# L4PER_PRM register map
Vendor: Texas Instruments
Registers are 32-bit, access per field, reset 0x0 unless marked. A register's access mark holds for its fields unless they carry their own. Offsets are as the file gives them; [hi:lo] are bit positions; {n}, {i} and the like mark numbered series; 'fields as' and 'values as' point back to an identical list.

## L4PER_PRM (part 2 of 2)
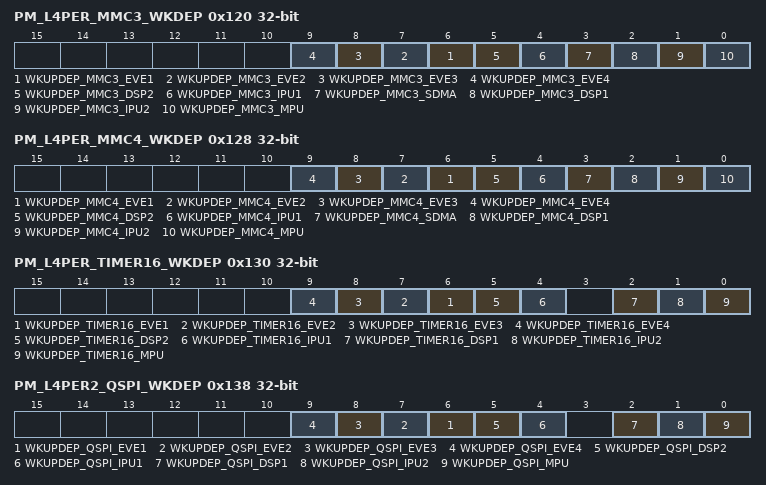
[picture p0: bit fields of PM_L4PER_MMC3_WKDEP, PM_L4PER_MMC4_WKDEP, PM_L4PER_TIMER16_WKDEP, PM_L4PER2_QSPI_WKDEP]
0x120 PM_L4PER_MMC3_WKDEP — This register controls wakeup dependency based on MMC3 service requests.
  [all] fields
    0=DISABLED (Dependency is disabled); 1=ENABLED (Dependency is enabled)
  [n+5] WKUPDEP_MMC3_EVE{n} rw (n=1..4) — Wakeup dependency from MMC3 module (SWakeup signal) towards EVE{n} + L3_MAIN1 + L4PER1 + L4PER2 + L4PER3 domains
  [5] WKUPDEP_MMC3_DSP2 rw — Wakeup dependency from MMC3 module (SWakeup signal) towards DSP2 + L3_MAIN1 + L4PER1 + L4PER2 + L4PER3 domains
  [4] WKUPDEP_MMC3_IPU1 rw — Wakeup dependency from MMC3 module (SWakeup signal) towards IPU1 + L3_MAIN1 + L4PER1 + L4PER2 + L4PER3 domains
  [3] WKUPDEP_MMC3_SDMA rw — Wakeup dependency from MMC3 module (SWakeup signal) towards SDMA + L3MAIN1 + L4PER1 + L4PER2 + L4PER3 domains
  [2] WKUPDEP_MMC3_DSP1 rw — Wakeup dependency from MMC3 module (SWakeup signal) towards DSP + L3MAIN1 + L4PER1 + L4PER2 + L4PER3 domains
  [1] WKUPDEP_MMC3_IPU2 rw — Wakeup dependency from MMC3 module (SWakeup signal) towards IPU2 + L3_MAIN1 + L4PER1 + L4PER2 + L4PER3 domains
  [0] WKUPDEP_MMC3_MPU rw — Wakeup dependency from MMC3 module (SWakeup signal) towards MPU + L3_MAIN1 + L4PER1 + L4PER2 + L4PER3 domains
0x128 PM_L4PER_MMC4_WKDEP — This register controls wakeup dependency based on MMC4 service requests.
  [all] fields
    values as the fields of PM_L4PER_MMC3_WKDEP
  [n+5] WKUPDEP_MMC4_EVE{n} rw (n=1..4) — Wakeup dependency from MMC4 module (SWakeup signal) towards EVE{n} + L3_MAIN1 + L4PER1 + L4PER2 + L4PER3 domains
  [5] WKUPDEP_MMC4_DSP2 rw — Wakeup dependency from MMC4 module (SWakeup signal) towards DSP2 + L3_MAIN1 + L4PER1 + L4PER2 + L4PER3 domains
  [4] WKUPDEP_MMC4_IPU1 rw — Wakeup dependency from MMC4 module (SWakeup signal) towards IPU1 + L3_MAIN1 + L4PER1 + L4PER2 + L4PER3 domains
  [3] WKUPDEP_MMC4_SDMA rw — Wakeup dependency from MMC4 module (SWakeup signal) towards SDMA + L3MAIN1 + L4PER1 + L4PER2 + L4PER3 domains
  [2] WKUPDEP_MMC4_DSP1 rw — Wakeup dependency from MMC4 module (SWakeup signal) towards DSP + L3MAIN1 + L4PER1 + L4PER2 + L4PER3 domains
  [1] WKUPDEP_MMC4_IPU2 rw — Wakeup dependency from MMC4 module (SWakeup signal) towards IPU2 + L3_MAIN1 + L4PER1 + L4PER2 + L4PER3 domains
  [0] WKUPDEP_MMC4_MPU rw — Wakeup dependency from MMC4 module (SWakeup signal) towards MPU + L3_MAIN1 + L4PER1 + L4PER2 + L4PER3 domains
0x130 PM_L4PER_TIMER16_WKDEP — This register controls wakeup dependency based on TIMER16 service requests.
  [all] fields
    values as the fields of PM_L4PER_MMC3_WKDEP
  [n+5] WKUPDEP_TIMER16_EVE{n} rw (n=1..4) — Wakeup dependency from TIMER16 module (SWakeup IRQ signal) towards EVE{n} + L3_MAIN1 + L4PER1 + L4PER2 + L4PER3 domains
  [5] WKUPDEP_TIMER16_DSP2 rw — Wakeup dependency from TIMER16 module (SWakeup IRQ signal) towards DSP2 + L3_MAIN1 + L4PER1 + L4PER2 + L4PER3 domains
  [4] WKUPDEP_TIMER16_IPU1 rw — Wakeup dependency from TIMER16 module (SWakeup IRQ signal) towards IPU1 + L3_MAIN1 + L4PER1 + L4PER2 + L4PER3 domains
  [2] WKUPDEP_TIMER16_DSP1 rw — Wakeup dependency from TIMER16 module (SWakeup IRQ signal) towards DSP + L3MAIN1 + L4PER1 + L4PER2 + L4PER3 domains
  [1] WKUPDEP_TIMER16_IPU2 rw — Wakeup dependency from TIMER16 module (SWakeup IRQ signal) towards IPU2 + L3_MAIN1 + L4PER1 + L4PER2 + L4PER3 domains
  [0] WKUPDEP_TIMER16_MPU rw — 6Wakeup dependency from TIMER16 module (SWakeup IRQ signal) towards MPU + L3_MAIN1 + L4PER1 + L4PER2 + L4PER3 domains
0x138 PM_L4PER2_QSPI_WKDEP — This register controls wakeup dependency based on QSPI service requests.
  [all] fields
    values as the fields of PM_L4PER_MMC3_WKDEP
  [n+5] WKUPDEP_QSPI_EVE{n} rw (n=1..4) — Wakeup dependency from QSPI module (SWakeup IRQ signal) towards EVE{n} + L3_MAIN1 + L4PER1 + L4PER2 + L4PER3 domains
  [5] WKUPDEP_QSPI_DSP2 rw — Wakeup dependency from QSPI module (SWakeup IRQ signal) towards DSP2 + L3_MAIN1 + L4PER1 + L4PER2 + L4PER3 domains
  [4] WKUPDEP_QSPI_IPU1 rw — Wakeup dependency from QSPI module (SWakeup IRQ signal) towards IPU1 + L3_MAIN1 + L4PER1 + L4PER2 + L4PER3 domains
  [2] WKUPDEP_QSPI_DSP1 rw — Wakeup dependency from QSPI module (SWakeup IRQ signal) towards DSP + L3MAIN1 + L4PER1 + L4PER2 + L4PER3 domains
  [1] WKUPDEP_QSPI_IPU2 rw — Wakeup dependency from QSPI module (SWakeup IRQ signal) towards IPU2 + L3_MAIN1 + L4PER1 + L4PER2 + L4PER3 domains
  [0] WKUPDEP_QSPI_MPU rw — Wakeup dependency from QSPI module (SWakeup IRQ signal) towards MPU + L3_MAIN1 + L4PER1 + L4PER2 + L4PER3 domains
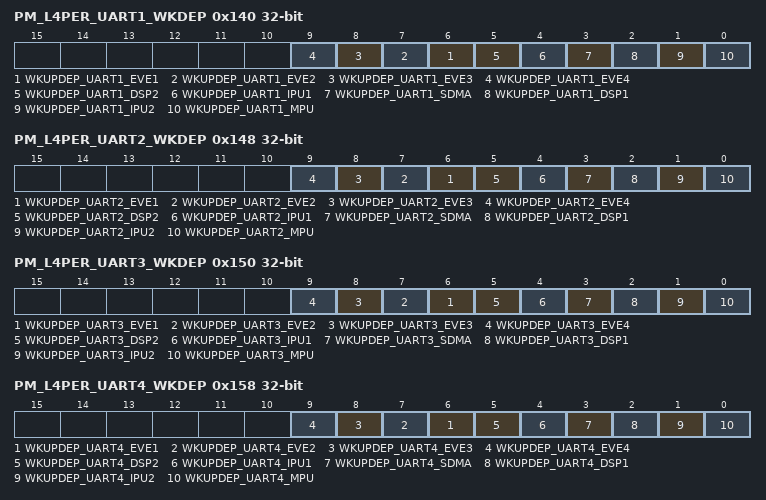
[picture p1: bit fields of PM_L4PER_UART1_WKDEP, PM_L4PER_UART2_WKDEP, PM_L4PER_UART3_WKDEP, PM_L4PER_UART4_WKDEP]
0x140 PM_L4PER_UART1_WKDEP — This register controls wakeup dependency based on UART1 service requests.
  [all] fields
    values as the fields of PM_L4PER_MMC3_WKDEP
  [n+5] WKUPDEP_UART1_EVE{n} rw (n=1..4) — Wakeup dependency from UART1 module (SWakeup signal) towards EVE{n} + L3_MAIN1 + L4PER1 + L4PER2 + L4PER3 domains
  [5] WKUPDEP_UART1_DSP2 rw — Wakeup dependency from UART1 module (SWakeup signal) towards DSP2 + L3_MAIN1 + L4PER1 + L4PER2 + L4PER3 domains
  [4] WKUPDEP_UART1_IPU1 rw — Wakeup dependency from UART1 module (SWakeup signal) towards IPU1 + L3_MAIN1 + L4PER1 + L4PER2 + L4PER3 domains
  [3] WKUPDEP_UART1_SDMA rw — Wakeup dependency from UART1 module (SWakeup signal) towards SDMA + L3MAIN1 + L4PER1 + L4PER2 + L4PER3 domains
  [2] WKUPDEP_UART1_DSP1 rw — Wakeup dependency from UART1 module (SWakeup signal) towards DSP + L3MAIN1 + L4PER1 + L4PER2 + L4PER3 domains
  [1] WKUPDEP_UART1_IPU2 rw — Wakeup dependency from UART1 module (SWakeup signal) towards IPU2 + L3_MAIN1 + L4PER1 + L4PER2 + L4PER3 domains
  [0] WKUPDEP_UART1_MPU rw — Wakeup dependency from UART1 module (SWakeup signal) towards MPU + L3_MAIN1 + L4PER1 + L4PER2 + L4PER3 domains
0x148 PM_L4PER_UART2_WKDEP — This register controls wakeup dependency based on UART2 service requests.
  [all] fields
    values as the fields of PM_L4PER_MMC3_WKDEP
  [n+5] WKUPDEP_UART2_EVE{n} rw (n=1..4) — Wakeup dependency from UART2 module (SWakeup signal) towards EVE{n} + L3_MAIN1 + L4PER1 + L4PER2 + L4PER3 domains
  [5] WKUPDEP_UART2_DSP2 rw — Wakeup dependency from UART2 module (SWakeup signal) towards DSP2 + L3_MAIN1 + L4PER1 + L4PER2 + L4PER3 domains
  [4] WKUPDEP_UART2_IPU1 rw — Wakeup dependency from UART2 module (SWakeup signal) towards IPU1 + L3_MAIN1 + L4PER1 + L4PER2 + L4PER3 domains
  [3] WKUPDEP_UART2_SDMA rw — 2Wakeup dependency from UART2 module (SWakeup signal) towards SDMA + L3MAIN1 + L4PER1 + L4PER2 + L4PER3 domains
  [2] WKUPDEP_UART2_DSP1 rw — Wakeup dependency from UART2 module (SWakeup signal) towards DSP + L3MAIN1 + L4PER1 + L4PER2 + L4PER3 domains
  [1] WKUPDEP_UART2_IPU2 rw — Wakeup dependency from UART2 module (SWakeup signal) towards IPU2 + L3_MAIN1 + L4PER1 + L4PER2 + L4PER3 domains
  [0] WKUPDEP_UART2_MPU rw — Wakeup dependency from UART2 module (SWakeup signal) towards MPU + L3_MAIN1 + L4PER1 + L4PER2 + L4PER3 domains
0x150 PM_L4PER_UART3_WKDEP — This register controls wakeup dependency based on UART3 service requests.
  [all] fields
    values as the fields of PM_L4PER_MMC3_WKDEP
  [n+5] WKUPDEP_UART3_EVE{n} rw (n=1..4) — Wakeup dependency from UART3 module (SWakeup signal) towards EVE{n} + L3_MAIN1 + L4PER1 + L4PER2 + L4PER3 domains
  [5] WKUPDEP_UART3_DSP2 rw — Wakeup dependency from UART3 module (SWakeup signal) towards DSP2 + L3_MAIN1 + L4PER1 + L4PER2 + L4PER3 domains
  [4] WKUPDEP_UART3_IPU1 rw — Wakeup dependency from UART3 module (SWakeup signal) towards IPU1 + L3_MAIN1 + L4PER1 + L4PER2 + L4PER3 domains
  [3] WKUPDEP_UART3_SDMA rw — Wakeup dependency from UART3 module (SWakeup signal) towards SDMA + L3MAIN1 + L4PER1 + L4PER2 + L4PER3 domains
  [2] WKUPDEP_UART3_DSP1 rw — Wakeup dependency from UART3 module (SWakeup signal) towards DSP + L3MAIN1 + L4PER1 + L4PER2 + L4PER3 domains
  [1] WKUPDEP_UART3_IPU2 rw — Wakeup dependency from UART3 module (SWakeup signal) towards IPU2 + L3_MAIN1 + L4PER1 + L4PER2 + L4PER3 domains
  [0] WKUPDEP_UART3_MPU rw — Wakeup dependency from UART3 module (SWakeup signal) towards MPU + L3_MAIN1 + L4PER1 + L4PER2 + L4PER3 domains
0x158 PM_L4PER_UART4_WKDEP — This register controls wakeup dependency based on UART4 service requests.
  [all] fields
    values as the fields of PM_L4PER_MMC3_WKDEP
  [n+5] WKUPDEP_UART4_EVE{n} rw (n=1..4) — Wakeup dependency from UART4 module (SWakeup signal) towards EVE{n} + L3_MAIN1 + L4PER1 + L4PER2 + L4PER3 domains
  [5] WKUPDEP_UART4_DSP2 rw — Wakeup dependency from UART4 module (SWakeup signal) towards DSP2 + L3_MAIN1 + L4PER1 + L4PER2 + L4PER3 domains
  [4] WKUPDEP_UART4_IPU1 rw — Wakeup dependency from UART4 module (SWakeup signal) towards IPU1 + L3_MAIN1 + L4PER1 + L4PER2 + L4PER3 domains
  [3] WKUPDEP_UART4_SDMA rw — Wakeup dependency from UART4 module (SWakeup signal) towards SDMA + L3MAIN1 + L4PER1 + L4PER2 + L4PER3 domains
  [2] WKUPDEP_UART4_DSP1 rw — Wakeup dependency from UART4 module (SWakeup signal) towards DSP + L3MAIN1 + L4PER1 + L4PER2 + L4PER3 domains
  [1] WKUPDEP_UART4_IPU2 rw — Wakeup dependency from UART4 module (SWakeup signal) towards IPU2 + L3_MAIN1 + L4PER1 + L4PER2 + L4PER3 domains
  [0] WKUPDEP_UART4_MPU rw — Wakeup dependency from UART4 module (SWakeup signal) towards MPU + L3_MAIN1 + L4PER1 + L4PER2 + L4PER3 domains
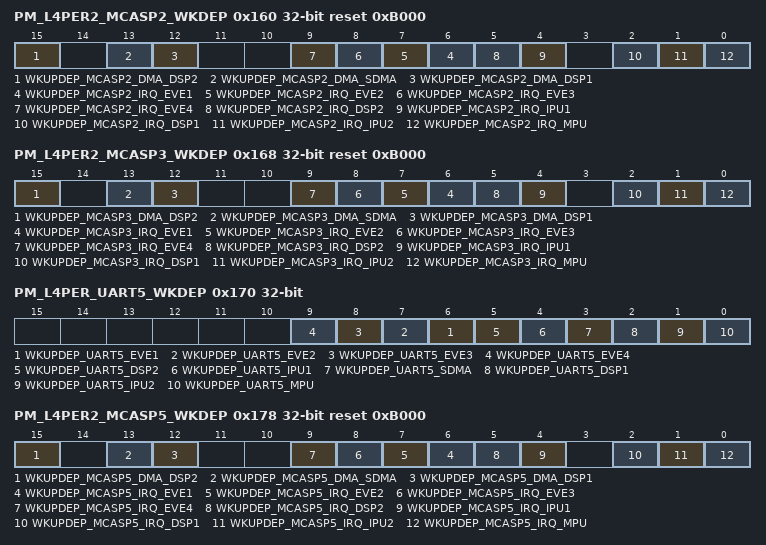
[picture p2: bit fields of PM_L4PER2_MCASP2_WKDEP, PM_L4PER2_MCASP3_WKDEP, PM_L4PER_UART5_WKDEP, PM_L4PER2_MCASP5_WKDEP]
0x160 PM_L4PER2_MCASP2_WKDEP reset 0xB000 — This register controls wakeup dependency based on MCASP2 service requests.
  [all] fields
    values as the fields of PM_L4PER_MMC3_WKDEP
  [15] WKUPDEP_MCASP2_DMA_DSP2 rw — Wakeup dependency from MCASP2 module (SWakeup_dma signal) towards DSP2 + L3_MAIN1 + L4PER1 + L4PER2 + L4PER3 domains
  [13] WKUPDEP_MCASP2_DMA_SDMA rw — Wakeup dependency from MCASP2 module (SWakeup_dma signal) towards SDMA + L3MAIN1 + L4PER1 + L4PER2 + L4PER3 domains
  [12] WKUPDEP_MCASP2_DMA_DSP1 rw — Wakeup dependency from MCASP2 module (SWakeup_dma signal) towards DSP + L3MAIN1 + L4PER1 + L4PER2 + L4PER3 domains
  [n+5] WKUPDEP_MCASP2_IRQ_EVE{n} rw (n=1..4) — Wakeup dependency from MCASP2 module (SWakeup IRQ signal) towards EVE{n} + L3_MAIN1 + L4PER1 + L4PER2 + L4PER3 domains
  [5] WKUPDEP_MCASP2_IRQ_DSP2 rw — Wakeup dependency from MCASP2 module (SWakeup IRQ signal) towards DSP2 + L3_MAIN1 + L4PER1 + L4PER2 + L4PER3 domains
  [4] WKUPDEP_MCASP2_IRQ_IPU1 rw — Wakeup dependency from MCASP2 module (SWakeup IRQ signal) towards IPU1 + L3_MAIN1 + L4PER1 + L4PER2 + L4PER3 domains
  [2] WKUPDEP_MCASP2_IRQ_DSP1 rw — Wakeup dependency from MCASP2 module (SWakeup IRQ signal) towards DSP + L3MAIN1 + L4PER1 + L4PER2 + L4PER3 domains
  [1] WKUPDEP_MCASP2_IRQ_IPU2 rw — Wakeup dependency from MCASP2 module (SWakeup IRQ signal) towards IPU2 + L3_MAIN1 + L4PER1 + L4PER2 + L4PER3 domains
  [0] WKUPDEP_MCASP2_IRQ_MPU rw — Wakeup dependency from MCASP2 module (SWakeup IRQ signal) towards MPU + L3_MAIN1 + L4PER1 + L4PER2 + L4PER3 domains
0x168 PM_L4PER2_MCASP3_WKDEP reset 0xB000 — This register controls wakeup dependency based on MCASP3 service requests.
  [all] fields
    values as the fields of PM_L4PER_MMC3_WKDEP
  [15] WKUPDEP_MCASP3_DMA_DSP2 rw — Wakeup dependency from MCASP3 module (SWakeup_dma signal) towards DSP2 + L3_MAIN1 + L4PER1 + L4PER2 + L4PER3 domains
  [13] WKUPDEP_MCASP3_DMA_SDMA rw — Wakeup dependency from MCASP3 module (SWakeup_dma signal) towards SDMA + L3MAIN1 + L4PER1 + L4PER2 + L4PER3 domains
  [12] WKUPDEP_MCASP3_DMA_DSP1 rw — 3Wakeup dependency from MCASP3 module (SWakeup_dma signal) towards DSP + L3MAIN1 + L4PER1 + L4PER2 + L4PER3 domains
  [n+5] WKUPDEP_MCASP3_IRQ_EVE{n} rw (n=1..4) — Wakeup dependency from MCASP3 module (SWakeup IRQ signal) towards EVE{n} + L3_MAIN1 + L4PER1 + L4PER2 + L4PER3 domains
  [5] WKUPDEP_MCASP3_IRQ_DSP2 rw — Wakeup dependency from MCASP3 module (SWakeup IRQ signal) towards DSP2 + L3_MAIN1 + L4PER1 + L4PER2 + L4PER3 domains
  [4] WKUPDEP_MCASP3_IRQ_IPU1 rw — Wakeup dependency from MCASP3 module (SWakeup IRQ signal) towards IPU1 + L3_MAIN1 + L4PER1 + L4PER2 + L4PER3 domains
  [2] WKUPDEP_MCASP3_IRQ_DSP1 rw — Wakeup dependency from MCASP3 module (SWakeup IRQ signal) towards DSP + L3MAIN1 + L4PER1 + L4PER2 + L4PER3 domains
  [1] WKUPDEP_MCASP3_IRQ_IPU2 rw — Wakeup dependency from MCASP3 module (SWakeup IRQ signal) towards IPU2 + L3_MAIN1 + L4PER1 + L4PER2 + L4PER3 domains
  [0] WKUPDEP_MCASP3_IRQ_MPU rw — Wakeup dependency from MCASP3 module (SWakeup IRQ signal) towards MPU + L3_MAIN1 + L4PER1 + L4PER2 + L4PER3 domains
0x170 PM_L4PER_UART5_WKDEP — This register controls wakeup dependency based on UART5 service requests.
  [all] fields
    values as the fields of PM_L4PER_MMC3_WKDEP
  [n+5] WKUPDEP_UART5_EVE{n} rw (n=1..4) — Wakeup dependency from UART5 module (SWakeup signal) towards EVE{n} + L3_MAIN1 + L4PER1 + L4PER2 + L4PER3 domains
  [5] WKUPDEP_UART5_DSP2 rw — Wakeup dependency from UART5 module (SWakeup signal) towards DSP2 + L3_MAIN1 + L4PER1 + L4PER2 + L4PER3 domains
  [4] WKUPDEP_UART5_IPU1 rw — Wakeup dependency from UART5 module (SWakeup signal) towards IPU1 + L3_MAIN1 + L4PER1 + L4PER2 + L4PER3 domains
  [3] WKUPDEP_UART5_SDMA rw — Wakeup dependency from UART5 module (SWakeup signal) towards SDMA + L3MAIN1 + L4PER1 + L4PER2 + L4PER3 domains
  [2] WKUPDEP_UART5_DSP1 rw — Wakeup dependency from UART5 module (SWakeup signal) towards DSP + L3MAIN1 + L4PER1 + L4PER2 + L4PER3 domains
  [1] WKUPDEP_UART5_IPU2 rw — Wakeup dependency from UART5 module (SWakeup signal) towards IPU2 + L3_MAIN1 + L4PER1 + L4PER2 + L4PER3 domains
  [0] WKUPDEP_UART5_MPU rw — Wakeup dependency from UART5 module (SWakeup signal) towards MPU + L3_MAIN1 + L4PER1 + L4PER2 + L4PER3 domains
0x178 PM_L4PER2_MCASP5_WKDEP reset 0xB000 — This register controls wakeup dependency based on MCASP5 service requests.
  [all] fields
    values as the fields of PM_L4PER_MMC3_WKDEP
  [15] WKUPDEP_MCASP5_DMA_DSP2 rw — Wakeup dependency from MCASP5 module (SWakeup_dma signal) towards DSP2 + L3_MAIN1 + L4PER1 + L4PER2 + L4PER3 domains
  [13] WKUPDEP_MCASP5_DMA_SDMA rw — Wakeup dependency from MCASP5 module (SWakeup_dma signal) towards SDMA + L3MAIN1 + L4PER1 + L4PER2 + L4PER3 domains
  [12] WKUPDEP_MCASP5_DMA_DSP1 rw — Wakeup dependency from MCASP5 module (SWakeup_dma signal) towards DSP + L3MAIN1 + L4PER1 + L4PER2 + L4PER3 domains
  [n+5] WKUPDEP_MCASP5_IRQ_EVE{n} rw (n=1..4) — Wakeup dependency from MCASP5 module (SWakeup IRQ signal) towards EVE{n} + L3_MAIN1 + L4PER1 + L4PER2 + L4PER3 domains
  [5] WKUPDEP_MCASP5_IRQ_DSP2 rw — Wakeup dependency from MCASP5 module (SWakeup IRQ signal) towards DSP2 + L3_MAIN1 + L4PER1 + L4PER2 + L4PER3 domains
  [4] WKUPDEP_MCASP5_IRQ_IPU1 rw — Wakeup dependency from MCASP5 module (SWakeup IRQ signal) towards IPU1 + L3_MAIN1 + L4PER1 + L4PER2 + L4PER3 domains
  [2] WKUPDEP_MCASP5_IRQ_DSP1 rw — Wakeup dependency from MCASP5 module (SWakeup IRQ signal) towards DSP + L3MAIN1 + L4PER1 + L4PER2 + L4PER3 domains
  [1] WKUPDEP_MCASP5_IRQ_IPU2 rw — Wakeup dependency from MCASP5 module (SWakeup IRQ signal) towards IPU2 + L3_MAIN1 + L4PER1 + L4PER2 + L4PER3 domains
  [0] WKUPDEP_MCASP5_IRQ_MPU rw — Wakeup dependency from MCASP5 module (SWakeup IRQ signal) towards MPU + L3_MAIN1 + L4PER1 + L4PER2 + L4PER3 domains
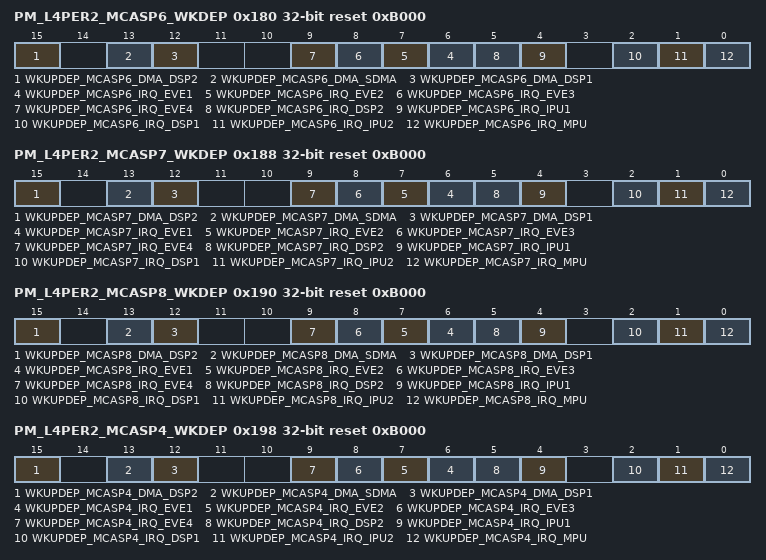
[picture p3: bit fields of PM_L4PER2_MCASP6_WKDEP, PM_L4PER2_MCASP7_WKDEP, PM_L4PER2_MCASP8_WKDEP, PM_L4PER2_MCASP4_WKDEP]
0x180 PM_L4PER2_MCASP6_WKDEP reset 0xB000 — This register controls wakeup dependency based on MCASP6 service requests.
  [all] fields
    values as the fields of PM_L4PER_MMC3_WKDEP
  [15] WKUPDEP_MCASP6_DMA_DSP2 rw — Wakeup dependency from MCASP6 module (SWakeup_dma signal) towards DSP2 + L3_MAIN1 + L4PER1 + L4PER2 + L4PER3 domains
  [13] WKUPDEP_MCASP6_DMA_SDMA rw — Wakeup dependency from MCASP6 module (SWakeup_dma signal) towards SDMA + L3MAIN1 + L4PER1 + L4PER2 + L4PER3 domains
  [12] WKUPDEP_MCASP6_DMA_DSP1 rw — Wakeup dependency from MCASP6 module (SWakeup_dma signal) towards DSP + L3MAIN1 + L4PER1 + L4PER2 + L4PER3 domains
  [n+5] WKUPDEP_MCASP6_IRQ_EVE{n} rw (n=1..4) — Wakeup dependency from MCASP6 module (SWakeup IRQ signal) towards EVE{n} + L3_MAIN1 + L4PER1 + L4PER2 + L4PER3 domains
  [5] WKUPDEP_MCASP6_IRQ_DSP2 rw — Wakeup dependency from MCASP6 module (SWakeup IRQ signal) towards DSP2 + L3_MAIN1 + L4PER1 + L4PER2 + L4PER3 domains
  [4] WKUPDEP_MCASP6_IRQ_IPU1 rw — Wakeup dependency from MCASP6 module (SWakeup IRQ signal) towards IPU1 + L3_MAIN1 + L4PER1 + L4PER2 + L4PER3 domains
  [2] WKUPDEP_MCASP6_IRQ_DSP1 rw — Wakeup dependency from MCASP6 module (SWakeup IRQ signal) towards DSP + L3MAIN1 + L4PER1 + L4PER2 + L4PER3 domains
  [1] WKUPDEP_MCASP6_IRQ_IPU2 rw — Wakeup dependency from MCASP6 (SWakeup IRQ signal) towards IPU2 + L3_MAIN1 + L4PER1 + L4PER2 + L4PER3 domains
  [0] WKUPDEP_MCASP6_IRQ_MPU rw — Wakeup dependency from MCASP6 module (SWakeup IRQ signal) towards MPU + L3_MAIN1 + L4PER1 + L4PER2 + L4PER3 domains
0x188 PM_L4PER2_MCASP7_WKDEP reset 0xB000 — This register controls wakeup dependency based on MCASP7 service requests.
  [all] fields
    values as the fields of PM_L4PER_MMC3_WKDEP
  [15] WKUPDEP_MCASP7_DMA_DSP2 rw — Wakeup dependency from MCASP7 module (SWakeup_dma signal) towards DSP2 + L3_MAIN1 + L4PER1 + L4PER2 + L4PER3 domains
  [13] WKUPDEP_MCASP7_DMA_SDMA rw — Wakeup dependency from MCASP7 module (SWakeup_dma signal) towards SDMA + L3MAIN1 + L4PER1 + L4PER2 + L4PER3 domains
  [12] WKUPDEP_MCASP7_DMA_DSP1 rw — Wakeup dependency from MCASP7 module (SWakeup_dma signal) towards DSP + L3MAIN1 + L4PER1 + L4PER2 + L4PER3 domains
  [n+5] WKUPDEP_MCASP7_IRQ_EVE{n} rw (n=1..4) — Wakeup dependency from MCASP7 module (SWakeup IRQ signal) towards EVE{n} + L3_MAIN1 + L4PER1 + L4PER2 + L4PER3 domains
  [5] WKUPDEP_MCASP7_IRQ_DSP2 rw — Wakeup dependency from MCASP7 module (SWakeup IRQ signal) towards DSP2 + L3_MAIN1 + L4PER1 + L4PER2 + L4PER3 domains
  [4] WKUPDEP_MCASP7_IRQ_IPU1 rw — Wakeup dependency from MCASP7 module (SWakeup IRQ signal) towards IPU1 + L3_MAIN1 + L4PER1 + L4PER2 + L4PER3 domains
  [2] WKUPDEP_MCASP7_IRQ_DSP1 rw — Wakeup dependency from MCASP7 module (SWakeup IRQ signal) towards DSP + L3MAIN1 + L4PER1 + L4PER2 + L4PER3 domains
  [1] WKUPDEP_MCASP7_IRQ_IPU2 rw — Wakeup dependency from MCASP7 module (SWakeup IRQ signal) towards IPU2 + L3_MAIN1 + L4PER1 + L4PER2 + L4PER3 domains
  [0] WKUPDEP_MCASP7_IRQ_MPU rw — Wakeup dependency from MCASP7 module (SWakeup IRQ signal) towards MPU + L3_MAIN1 + L4PER1 + L4PER2 + L4PER3 domains
0x190 PM_L4PER2_MCASP8_WKDEP reset 0xB000 — This register controls wakeup dependency based on MCASP8 service requests.
  [all] fields
    values as the fields of PM_L4PER_MMC3_WKDEP
  [15] WKUPDEP_MCASP8_DMA_DSP2 rw — Wakeup dependency from MCASP8 module (SWakeup_dma signal) towards DSP2 + L3_MAIN1 + L4PER1 + L4PER2 + L4PER3 domains
  [13] WKUPDEP_MCASP8_DMA_SDMA rw — Wakeup dependency from MCASP8 module (SWakeup_dma signal) towards SDMA + L3MAIN1 + L4PER1 + L4PER2 + L4PER3 domains
  [12] WKUPDEP_MCASP8_DMA_DSP1 rw — Wakeup dependency from MCASP8 module (SWakeup_dma signal) towards DSP + L3MAIN1 + L4PER1 + L4PER2 + L4PER3 domains
  [n+5] WKUPDEP_MCASP8_IRQ_EVE{n} rw (n=1..4) — Wakeup dependency from MCASP8 module (SWakeup IRQ signal) towards EVE{n} + L3_MAIN1 + L4PER1 + L4PER2 + L4PER3 domains
  [5] WKUPDEP_MCASP8_IRQ_DSP2 rw — Wakeup dependency from MCASP8 module (SWakeup IRQ signal) towards DSP2 + L3_MAIN1 + L4PER1 + L4PER2 + L4PER3 domains
  [4] WKUPDEP_MCASP8_IRQ_IPU1 rw — Wakeup dependency from MCASP8 module (SWakeup IRQ signal) towards IPU1 + L3_MAIN1 + L4PER1 + L4PER2 + L4PER3 domains
  [2] WKUPDEP_MCASP8_IRQ_DSP1 rw — Wakeup dependency from MCASP8 module (SWakeup IRQ signal) towards DSP + L3MAIN1 + L4PER1 + L4PER2 + L4PER3 domains
  [1] WKUPDEP_MCASP8_IRQ_IPU2 rw — Wakeup dependency from MCASP8 module (SWakeup IRQ signal) towards IPU2 + L3_MAIN1 + L4PER1 + L4PER2 + L4PER3 domains
  [0] WKUPDEP_MCASP8_IRQ_MPU rw — Wakeup dependency from MCASP8 module (SWakeup IRQ signal) towards MPU + L3_MAIN1 + L4PER1 + L4PER2 + L4PER3 domains
0x198 PM_L4PER2_MCASP4_WKDEP reset 0xB000 — This register controls wakeup dependency based on MCASP4 service requests.
  [all] fields
    values as the fields of PM_L4PER_MMC3_WKDEP
  [15] WKUPDEP_MCASP4_DMA_DSP2 rw — Wakeup dependency from MCASP4 module (SWakeup_dma signal) towards DSP2 + L3_MAIN1 + L4PER1 + L4PER2 + L4PER3 domains
  [13] WKUPDEP_MCASP4_DMA_SDMA rw — Wakeup dependency from MCASP4 module (SWakeup_dma signal) towards SDMA + L3MAIN1 + L4PER1 + L4PER2 + L4PER3 domains
  [12] WKUPDEP_MCASP4_DMA_DSP1 rw — Wakeup dependency from MCASP4 module (SWakeup_dma signal) towards DSP + L3MAIN1 + L4PER1 + L4PER2 + L4PER3 domains
  [n+5] WKUPDEP_MCASP4_IRQ_EVE{n} rw (n=1..4) — Wakeup dependency from MCASP4 module (SWakeup IRQ signal) towards EVE{n} + L3_MAIN1 + L4PER1 + L4PER2 + L4PER3 domains
  [5] WKUPDEP_MCASP4_IRQ_DSP2 rw — Wakeup dependency from MCASP4 module (SWakeup IRQ signal) towards DSP2 + L3_MAIN1 + L4PER1 + L4PER2 + L4PER3 domains
  [4] WKUPDEP_MCASP4_IRQ_IPU1 rw — Wakeup dependency from MCASP4 module (SWakeup IRQ signal) towards IPU1 + L3_MAIN1 + L4PER1 + L4PER2 + L4PER3 domains
  [2] WKUPDEP_MCASP4_IRQ_DSP1 rw — Wakeup dependency from MCASP4 module (SWakeup IRQ signal) towards DSP + L3MAIN1 + L4PER1 + L4PER2 + L4PER3 domains
  [1] WKUPDEP_MCASP4_IRQ_IPU2 rw — Wakeup dependency from MCASP4 module (SWakeup IRQ signal) towards IPU2 + L3_MAIN1 + L4PER1 + L4PER2 + L4PER3 domains
  [0] WKUPDEP_MCASP4_IRQ_MPU rw — Wakeup dependency from MCASP4 module (SWakeup IRQ signal) towards MPU + L3_MAIN1 + L4PER1 + L4PER2 + L4PER3 domains
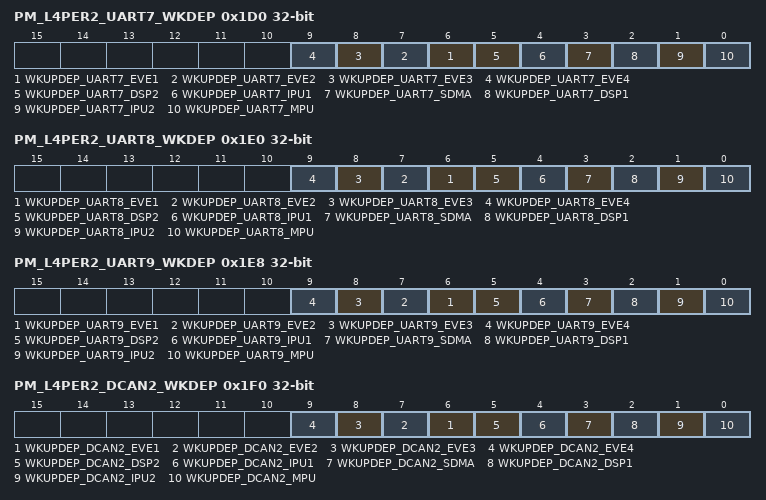
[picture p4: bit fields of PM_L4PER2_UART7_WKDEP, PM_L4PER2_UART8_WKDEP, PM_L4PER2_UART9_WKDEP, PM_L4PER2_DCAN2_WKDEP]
0x1D0 PM_L4PER2_UART7_WKDEP — This register controls wakeup dependency based on UART7 service requests.
  [all] fields
    values as the fields of PM_L4PER_MMC3_WKDEP
  [n+5] WKUPDEP_UART7_EVE{n} rw (n=1..4) — Wakeup dependency from UART7 module (SWakeup signal) towards EVE{n} + L3_MAIN1 + L4PER1 + L4PER2 + L4PER3 domains
  [5] WKUPDEP_UART7_DSP2 rw — Wakeup dependency from UART7 module (SWakeup signal) towards DSP2 + L3_MAIN1 + L4PER1 + L4PER2 + L4PER3 domains
  [4] WKUPDEP_UART7_IPU1 rw — Wakeup dependency from UART7 module (SWakeup signal) towards IPU1 + L3_MAIN1 + L4PER1 + L4PER2 + L4PER3 domains
  [3] WKUPDEP_UART7_SDMA rw — Wakeup dependency from UART7 module (SWakeup signal) towards SDMA + L3MAIN1 + L4PER1 + L4PER2 + L4PER3 domains
  [2] WKUPDEP_UART7_DSP1 rw — Wakeup dependency from UART7 module (SWakeup signal) towards DSP + L3MAIN1 + L4PER1 + L4PER2 + L4PER3 domains
  [1] WKUPDEP_UART7_IPU2 rw — Wakeup dependency from UART7 module (SWakeup signal) towards IPU2 + L3_MAIN1 + L4PER1 + L4PER2 + L4PER3 domains
  [0] WKUPDEP_UART7_MPU rw — Wakeup dependency from UART7 module (SWakeup signal) towards MPU + L3_MAIN1 + L4PER1 + L4PER2 + L4PER3 domains
0x1E0 PM_L4PER2_UART8_WKDEP — This register controls wakeup dependency based on UART8 service requests.
  [all] fields
    values as the fields of PM_L4PER_MMC3_WKDEP
  [n+5] WKUPDEP_UART8_EVE{n} rw (n=1..4) — Wakeup dependency from UART8 module (SWakeup signal) towards EVE{n} + L3_MAIN1 + L4PER1 + L4PER2 + L4PER3 domains
  [5] WKUPDEP_UART8_DSP2 rw — Wakeup dependency from UART8 module (SWakeup signal) towards DSP2 + L3_MAIN1 + L4PER1 + L4PER2 + L4PER3 domains
  [4] WKUPDEP_UART8_IPU1 rw — Wakeup dependency from UART8 module (SWakeup signal) towards IPU1 + L3_MAIN1 + L4PER1 + L4PER2 + L4PER3 domains
  [3] WKUPDEP_UART8_SDMA rw — Wakeup dependency from UART8 module (SWakeup signal) towards SDMA + L3MAIN1 + L4PER1 + L4PER2 + L4PER3 domains
  [2] WKUPDEP_UART8_DSP1 rw — Wakeup dependency from UART8 module (SWakeup signal) towards DSP + L3MAIN1 + L4PER1 + L4PER2 + L4PER3 domains
  [1] WKUPDEP_UART8_IPU2 rw — Wakeup dependency from UART8 module (SWakeup signal) towards IPU2 + L3_MAIN1 + L4PER1 + L4PER2 + L4PER3 domains
  [0] WKUPDEP_UART8_MPU rw — Wakeup dependency from UART8 module (SWakeup signal) towards MPU + L3_MAIN1 + L4PER1 + L4PER2 + L4PER3 domains
0x1E8 PM_L4PER2_UART9_WKDEP — This register controls wakeup dependency based on UART9 service requests.
  [all] fields
    values as the fields of PM_L4PER_MMC3_WKDEP
  [n+5] WKUPDEP_UART9_EVE{n} rw (n=1..4) — Wakeup dependency from UART9 module (SWakeup signal) towards EVE{n} + L3_MAIN1 + L4PER1 + L4PER2 + L4PER3 domains
  [5] WKUPDEP_UART9_DSP2 rw — Wakeup dependency from UART9 module (SWakeup signal) towards DSP2 + L3_MAIN1 + L4PER1 + L4PER2 + L4PER3 domains
  [4] WKUPDEP_UART9_IPU1 rw — Wakeup dependency from UART9 module (SWakeup signal) towards IPU1 + L3_MAIN1 + L4PER1 + L4PER2 + L4PER3 domains
  [3] WKUPDEP_UART9_SDMA rw — Wakeup dependency from UART9 module (SWakeup signal) towards SDMA + L3MAIN1 + L4PER1 + L4PER2 + L4PER3 domains
  [2] WKUPDEP_UART9_DSP1 rw — Wakeup dependency from UART9 module (SWakeup signal) towards DSP + L3MAIN1 + L4PER1 + L4PER2 + L4PER3 domains
  [1] WKUPDEP_UART9_IPU2 rw — Wakeup dependency from UART9 module (SWakeup signal) towards IPU2 + L3_MAIN1 + L4PER1 + L4PER2 + L4PER3 domains
  [0] WKUPDEP_UART9_MPU rw — Wakeup dependency from UART9 module (SWakeup signal) towards MPU + L3_MAIN1 + L4PER1 + L4PER2 + L4PER3 domains
0x1F0 PM_L4PER2_DCAN2_WKDEP — This register controls wakeup dependency based on DCAN2 service requests.
  [all] fields
    values as the fields of PM_L4PER_MMC3_WKDEP
  [n+5] WKUPDEP_DCAN2_EVE{n} rw (n=1..4) — Wakeup dependency from DCAN2 module (SWakeup signal) towards EVE{n} + L3_MAIN1 + L4PER1 + L4PER2 + L4PER3 domains
  [5] WKUPDEP_DCAN2_DSP2 rw — Wakeup dependency from DCAN2 module (SWakeup signal) towards DSP2 + L3_MAIN1 + L4PER1 + L4PER2 + L4PER3 domains
  [4] WKUPDEP_DCAN2_IPU1 rw — Wakeup dependency from DCAN2 module (SWakeup signal) towards IPU1 + L3_MAIN1 + L4PER1 + L4PER2 + L4PER3 domains
  [3] WKUPDEP_DCAN2_SDMA rw — Wakeup dependency from DCAN2 module (SWakeup signal) towards SDMA + L3MAIN1 + L4PER1 + L4PER2 + L4PER3 domains
  [2] WKUPDEP_DCAN2_DSP1 rw — Wakeup dependency from DCAN2 module (SWakeup signal) towards DSP + L3MAIN1 + L4PER1 + L4PER2 + L4PER3 domains
  [1] WKUPDEP_DCAN2_IPU2 rw — Wakeup dependency from DCAN2 module (SWakeup signal) towards IPU2 + L3_MAIN1 + L4PER1 + L4PER2 + L4PER3 domains
  [0] WKUPDEP_DCAN2_MPU rw — Wakeup dependency from DCAN2 module (SWakeup signal) towards MPU + L3_MAIN1 + L4PER1 + L4PER2 + L4PER3 domains
